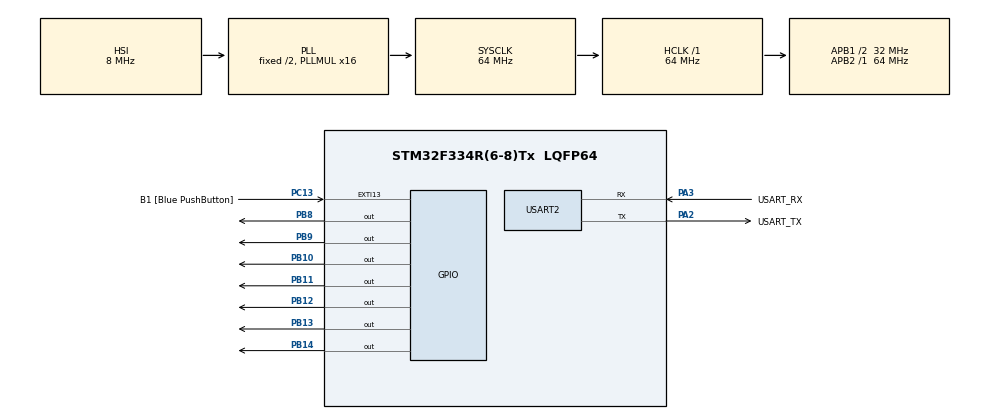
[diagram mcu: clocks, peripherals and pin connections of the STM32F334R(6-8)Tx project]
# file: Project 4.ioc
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Mcu.Family=STM32F3
Mcu.Name=STM32F334R(6-8)Tx
Mcu.Package=LQFP64
NVIC.PriorityGroup=NVIC_PRIORITYGROUP_0
PA13.GPIO_Label=TMS
PA13.Mode=Serial_Wire
PA13.Signal=SYS_JTMS-SWDIO
PA14.GPIO_Label=TCK
PA14.Mode=Serial_Wire
PA14.Signal=SYS_JTCK-SWCLK
PA2.GPIO_Label=USART_TX
PA2.Mode=Asynchronous
PA2.Signal=USART2_TX
PA3.GPIO_Label=USART_RX
PA3.Mode=Asynchronous
PA3.Signal=USART2_RX
PB10.GPIO_ModeDefaultOutputPP=GPIO_MODE_OUTPUT_OD
PB10.GPIO_PuPd=GPIO_NOPULL
PB10.Signal=GPIO_Output
PB11.GPIO_ModeDefaultOutputPP=GPIO_MODE_OUTPUT_OD
PB11.GPIO_PuPd=GPIO_NOPULL
PB11.Signal=GPIO_Output
PB12.GPIO_ModeDefaultOutputPP=GPIO_MODE_OUTPUT_OD
PB12.GPIO_PuPd=GPIO_NOPULL
PB12.Signal=GPIO_Output
PB13.GPIO_ModeDefaultOutputPP=GPIO_MODE_OUTPUT_OD
PB13.GPIO_PuPd=GPIO_NOPULL
PB13.Signal=GPIO_Output
PB14.GPIO_ModeDefaultOutputPP=GPIO_MODE_OUTPUT_OD
PB14.GPIO_PuPd=GPIO_NOPULL
PB14.Signal=GPIO_Output
PB3.GPIO_Label=SWO
PB3.Signal=SYS_JTDO-TRACESWO
PB8.GPIO_ModeDefaultOutputPP=GPIO_MODE_OUTPUT_OD
PB8.GPIO_PuPd=GPIO_NOPULL
PB8.Signal=GPIO_Output
PB9.GPIO_ModeDefaultOutputPP=GPIO_MODE_OUTPUT_OD
PB9.GPIO_PuPd=GPIO_NOPULL
PB9.Signal=GPIO_Output
PC13.GPIO_Label=B1 [Blue PushButton]
PC13.GPIO_ModeDefaultEXTI=GPIO_MODE_IT_FALLING
PC13.Signal=GPXTI13
PC14\ /\ OSC32_IN.Mode=LSE-External-Oscillator
PC14\ /\ OSC32_IN.Signal=RCC_OSC32_IN
PC15\ /\ OSC32_OUT.GPIO_Label=RCC_OSC32_OUT
PC15\ /\ OSC32_OUT.Mode=LSE-External-Oscillator
PC15\ /\ OSC32_OUT.Signal=RCC_OSC32_OUT
PF0\ /\ OSC_IN.Mode=HSE-External-Clock-Source
PF0\ /\ OSC_IN.Signal=RCC_OSC_IN
PF1\ /\ OSC_OUT.Signal=RCC_OSC_OUT
ProjectManager.HeapSize=0x200
ProjectManager.StackSize=0x400
ProjectManager.TargetToolchain=STM32CubeIDE
RCC.AHBFreq_Value=64000000
RCC.APB1CLKDivider=RCC_HCLK_DIV2
RCC.APB1Freq_Value=32000000
RCC.APB1TimFreq_Value=64000000
RCC.APB2Freq_Value=64000000
RCC.APB2TimFreq_Value=64000000
RCC.CortexFreq_Value=64000000
RCC.FLatency-AdvancedSettings=FLASH_LATENCY_2
RCC.HCLKFreq_Value=64000000
RCC.HSE_VALUE=8000000
RCC.HSI_VALUE=8000000
RCC.PLLMUL=RCC_PLL_MUL16
RCC.SYSCLKFreq_VALUE=64000000
RCC.SYSCLKSourceVirtual=RCC_SYSCLKSOURCE_PLLCLK
USART2.VirtualMode-Asynchronous=VM_ASYNC
board=NUCLEO-F334R8

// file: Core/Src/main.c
/* USER CODE BEGIN Header */
/**
  ******************************************************************************
  * @file           : main.c
  * @brief          : Main program body
  ******************************************************************************
  * @attention
  *
  * Copyright (c) 2022 STMicroelectronics.
  * All rights reserved.
  *
  * This software is licensed under terms that can be found in the LICENSE file
  * in the root directory of this software component.
  * If no LICENSE file comes with this software, it is provided AS-IS.
  *
  ******************************************************************************
  */
/* USER CODE END Header */
#include "main.h"

UART_HandleTypeDef huart2;

void SystemClock_Config(void);
static void MX_GPIO_Init(void);
static void MX_USART2_UART_Init(void);

int main(void)
{

  /* MCU Configuration--------------------------------------------------------*/

  /* Reset of all peripherals, Initializes the Flash interface and the Systick. */
  HAL_Init();

  /* Configure the system clock */
  SystemClock_Config();

  /* Initialize all configured peripherals */
  MX_GPIO_Init();
  MX_USART2_UART_Init();
  /* USER CODE BEGIN 2 */
  #define LED11 GPIO_PIN_8
  #define LED12 GPIO_PIN_9
  #define LED13 GPIO_PIN_10
  #define LED14 GPIO_PIN_11
  #define LED15 GPIO_PIN_12
  #define LED16 GPIO_PIN_13
  #define LED17 GPIO_PIN_14
  uint16_t Count = 0;
  /* USER CODE END 2 */

  /* Infinite loop */
  /* USER CODE BEGIN WHILE */
    while (1)
    {
    	GPIOB->ODR = ~(Count<<8); 	// GPIOB->ODR is the name of the registry where you write the value
    								// you want the pins to output. It has 16 bits, for the 16 pins of port B
    								// <<8 Displaces bits of Count 8 positions to the left
    								// (because we use pins 8 to 14): 0000000000000111 -> 0000011100000000
    								// ~ Negate bits: 0000011100000000 -> 1111100011111111
    		  HAL_Delay (500);

    		  if (Count==128)  Count = 0;		//reset counter
    		  else Count++;
    	    /* USER CODE END WHILE */

    }
}

void SystemClock_Config(void)
{
  RCC_OscInitTypeDef RCC_OscInitStruct = {0};
  RCC_ClkInitTypeDef RCC_ClkInitStruct = {0};

  /** Initializes the RCC Oscillators according to the specified parameters
  * in the RCC_OscInitTypeDef structure.
  */
  RCC_OscInitStruct.OscillatorType = RCC_OSCILLATORTYPE_HSI;
  RCC_OscInitStruct.HSIState = RCC_HSI_ON;
  RCC_OscInitStruct.HSICalibrationValue = RCC_HSICALIBRATION_DEFAULT;
  RCC_OscInitStruct.PLL.PLLState = RCC_PLL_ON;
  RCC_OscInitStruct.PLL.PLLSource = RCC_PLLSOURCE_HSI;
  RCC_OscInitStruct.PLL.PLLMUL = RCC_PLL_MUL16;
  if (HAL_RCC_OscConfig(&RCC_OscInitStruct) != HAL_OK)
  {
    Error_Handler();
  }

  /** Initializes the CPU, AHB and APB buses clocks
  */
  RCC_ClkInitStruct.ClockType = RCC_CLOCKTYPE_HCLK|RCC_CLOCKTYPE_SYSCLK
                              |RCC_CLOCKTYPE_PCLK1|RCC_CLOCKTYPE_PCLK2;
  RCC_ClkInitStruct.SYSCLKSource = RCC_SYSCLKSOURCE_PLLCLK;
  RCC_ClkInitStruct.AHBCLKDivider = RCC_SYSCLK_DIV1;
  RCC_ClkInitStruct.APB1CLKDivider = RCC_HCLK_DIV2;
  RCC_ClkInitStruct.APB2CLKDivider = RCC_HCLK_DIV1;

  if (HAL_RCC_ClockConfig(&RCC_ClkInitStruct, FLASH_LATENCY_2) != HAL_OK)
  {
    Error_Handler();
  }
}

static void MX_USART2_UART_Init(void)
{

  huart2.Instance = USART2;
  huart2.Init.BaudRate = 38400;
  huart2.Init.WordLength = UART_WORDLENGTH_8B;
  huart2.Init.StopBits = UART_STOPBITS_1;
  huart2.Init.Parity = UART_PARITY_NONE;
  huart2.Init.Mode = UART_MODE_TX_RX;
  huart2.Init.HwFlowCtl = UART_HWCONTROL_NONE;
  huart2.Init.OverSampling = UART_OVERSAMPLING_16;
  huart2.Init.OneBitSampling = UART_ONE_BIT_SAMPLE_DISABLE;
  huart2.AdvancedInit.AdvFeatureInit = UART_ADVFEATURE_NO_INIT;
  if (HAL_UART_Init(&huart2) != HAL_OK)
  {
    Error_Handler();
  }

}

static void MX_GPIO_Init(void)
{
  GPIO_InitTypeDef GPIO_InitStruct = {0};

  /* GPIO Ports Clock Enable */
  __HAL_RCC_GPIOC_CLK_ENABLE();
  __HAL_RCC_GPIOF_CLK_ENABLE();
  __HAL_RCC_GPIOA_CLK_ENABLE();
  __HAL_RCC_GPIOB_CLK_ENABLE();

  /*Configure GPIO pin Output Level */
  HAL_GPIO_WritePin(GPIOB, GPIO_PIN_10|GPIO_PIN_11|GPIO_PIN_12|GPIO_PIN_13
                          |GPIO_PIN_14|GPIO_PIN_8|GPIO_PIN_9, GPIO_PIN_RESET);

  /*Configure GPIO pin : B1_Pin */
  GPIO_InitStruct.Pin = B1_Pin;
  GPIO_InitStruct.Mode = GPIO_MODE_IT_FALLING;
  GPIO_InitStruct.Pull = GPIO_NOPULL;
  HAL_GPIO_Init(B1_GPIO_Port, &GPIO_InitStruct);

  /*Configure GPIO pins : PB10 PB11 PB12 PB13
                           PB14 PB8 PB9 */
  GPIO_InitStruct.Pin = GPIO_PIN_10|GPIO_PIN_11|GPIO_PIN_12|GPIO_PIN_13
                          |GPIO_PIN_14|GPIO_PIN_8|GPIO_PIN_9;
  GPIO_InitStruct.Mode = GPIO_MODE_OUTPUT_OD;
  GPIO_InitStruct.Pull = GPIO_NOPULL;
  GPIO_InitStruct.Speed = GPIO_SPEED_FREQ_LOW;
  HAL_GPIO_Init(GPIOB, &GPIO_InitStruct);

}

void Error_Handler(void)
{
  __disable_irq();
  while (1)
  {
  }
}
